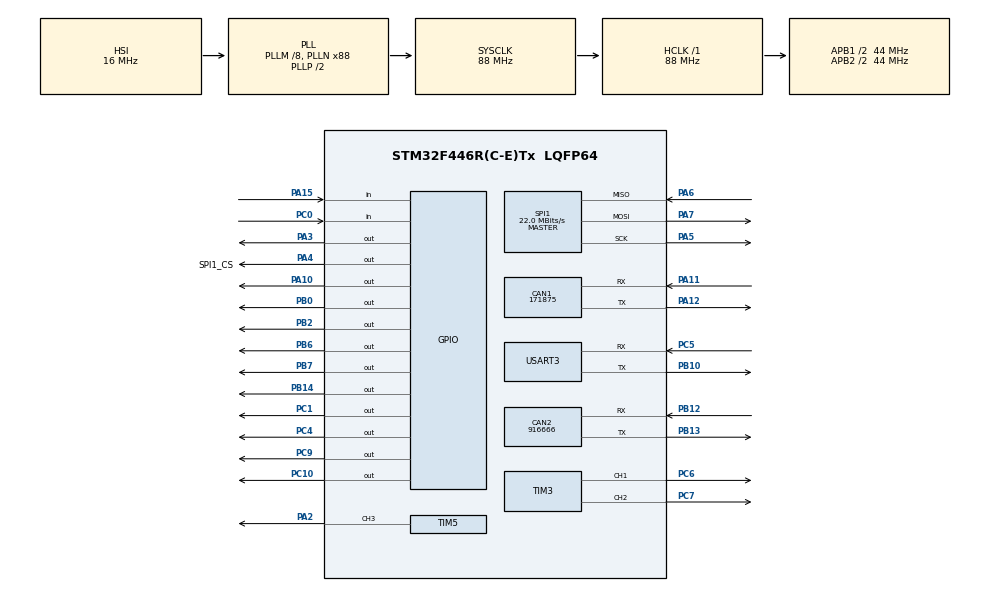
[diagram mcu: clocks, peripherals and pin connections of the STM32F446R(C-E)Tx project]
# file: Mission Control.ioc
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CAN1.AWUM=ENABLE
CAN1.BS1=CAN_BS1_13TQ
CAN1.BS2=CAN_BS2_2TQ
CAN1.CalculateBaudRate=171875
CAN1.CalculateTimeBit=5818
CAN1.CalculateTimeQuantum=363.6363636363636
CAN1.Mode=CAN_MODE_NORMAL
CAN1.NART=ENABLE
CAN2.CalculateBaudRate=916666
CAN2.CalculateTimeBit=1090
CAN2.CalculateTimeQuantum=363.6363636363636
Mcu.Family=STM32F4
Mcu.Name=STM32F446R(C-E)Tx
Mcu.Package=LQFP64
NVIC.PriorityGroup=NVIC_PRIORITYGROUP_4
PA10.Signal=GPIO_Output
PA11.Mode=CAN_Activate
PA11.Signal=CAN1_RX
PA12.Mode=CAN_Activate
PA12.Signal=CAN1_TX
PA13.Mode=Trace_Asynchronous_SW
PA13.Signal=SYS_JTMS-SWDIO
PA14.Mode=Trace_Asynchronous_SW
PA14.Signal=SYS_JTCK-SWCLK
PA15.Signal=GPIO_Input
PA2.Signal=S_TIM5_CH3
PA3.Signal=GPIO_Output
PA4.GPIO_Label=SPI1_CS
PA4.Signal=GPIO_Output
PA5.Mode=Full_Duplex_Master
PA5.Signal=SPI1_SCK
PA6.Mode=Full_Duplex_Master
PA6.Signal=SPI1_MISO
PA7.Mode=Full_Duplex_Master
PA7.Signal=SPI1_MOSI
PB0.Signal=GPIO_Output
PB10.Mode=Asynchronous
PB10.Signal=USART3_TX
PB12.Mode=CAN_Activate
PB12.Signal=CAN2_RX
PB13.Mode=CAN_Activate
PB13.Signal=CAN2_TX
PB14.Signal=GPIO_Output
PB2.Signal=GPIO_Output
PB3.Mode=Trace_Asynchronous_SW
PB3.Signal=SYS_JTDO-SWO
PB6.Signal=GPIO_Output
PB7.Signal=GPIO_Output
PB8.Signal=S_TIM2_CH1_ETR
PC0.Signal=GPIO_Input
PC1.Signal=GPIO_Output
PC10.Signal=GPIO_Output
PC14-OSC32_IN.Signal=RCC_OSC32_IN
PC15-OSC32_OUT.Signal=RCC_OSC32_OUT
PC4.Signal=GPIO_Output
PC5.Mode=Asynchronous
PC5.Signal=USART3_RX
PC6.Signal=S_TIM3_CH1
PC7.Signal=S_TIM3_CH2
PC9.Signal=GPIO_Output
PH0-OSC_IN.Mode=HSE-External-Oscillator
PH0-OSC_IN.Signal=RCC_OSC_IN
PH1-OSC_OUT.Mode=HSE-External-Oscillator
PH1-OSC_OUT.Signal=RCC_OSC_OUT
ProjectManager.HeapSize=0x200
ProjectManager.StackSize=0x400
ProjectManager.TargetToolchain=STM32CubeIDE
RCC.AHBFreq_Value=88000000
RCC.APB1CLKDivider=RCC_HCLK_DIV2
RCC.APB1Freq_Value=44000000
RCC.APB1TimFreq_Value=88000000
RCC.APB2CLKDivider=RCC_HCLK_DIV2
RCC.APB2Freq_Value=44000000
RCC.APB2TimFreq_Value=88000000
RCC.CortexFreq_Value=88000000
RCC.HCLKFreq_Value=88000000
RCC.HSE_VALUE=8000000
RCC.PLLM=8
RCC.PLLN=88
RCC.SYSCLKFreq_VALUE=88000000
RCC.SYSCLKSource=RCC_SYSCLKSOURCE_PLLCLK
RCC.USBFreq_Value=88000000
RCC.VCOOutputFreq_Value=176000000
SH.S_TIM2_CH1_ETR.0=TIM2_CH1
SH.S_TIM3_CH1.0=TIM3_CH1,PWM Generation1 CH1
SH.S_TIM3_CH2.0=TIM3_CH2,PWM Generation2 CH2
SH.S_TIM5_CH3.0=TIM5_CH3,PWM Generation3 CH3
SPI1.CalculateBaudRate=22.0 MBits/s
SPI1.Direction=SPI_DIRECTION_2LINES
SPI1.Mode=SPI_MODE_MASTER
SPI1.VirtualType=VM_MASTER
TIM3.Channel-PWM\ Generation1\ CH1=TIM_CHANNEL_1
TIM3.Channel-PWM\ Generation2\ CH2=TIM_CHANNEL_2
TIM5.Channel-PWM\ Generation3\ CH3=TIM_CHANNEL_3
TIM5.Period=19999
TIM5.Prescaler=87
USART3.VirtualMode=VM_ASYNC
VP_RTC_VS_RTC_Activate.Mode=RTC_Enabled
VP_TIM1_VS_ClockSourceINT.Mode=Internal
board=custom

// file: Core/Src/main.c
/* USER CODE BEGIN Header */
/**
  ******************************************************************************
  * @file           : main.c
  * @brief          : Main program body
  ******************************************************************************
  * @attention
  *
  * Copyright (c) 2025 STMicroelectronics.
  * All rights reserved.
  *
  * This software is licensed under terms that can be found in the LICENSE file
  * in the root directory of this software component.
  * If no LICENSE file comes with this software, it is provided AS-IS.
  *
  ******************************************************************************
  */
/* USER CODE END Header */
#include "main.h"

CAN_HandleTypeDef hcan1;
CAN_HandleTypeDef hcan2;

RTC_HandleTypeDef hrtc;

SPI_HandleTypeDef hspi1;

TIM_HandleTypeDef htim1;
TIM_HandleTypeDef htim3;
TIM_HandleTypeDef htim5;

UART_HandleTypeDef huart3;

void SystemClock_Config(void);
static void MX_GPIO_Init(void);
static void MX_RTC_Init(void);
static void MX_TIM1_Init(void);
static void MX_CAN1_Init(void);
static void MX_CAN2_Init(void);
static void MX_SPI1_Init(void);
static void MX_TIM5_Init(void);
static void MX_USART3_UART_Init(void);
static void MX_TIM3_Init(void);

int main(void)
{

  /* MCU Configuration--------------------------------------------------------*/

  /* Reset of all peripherals, Initializes the Flash interface and the Systick. */
  HAL_Init();

  /* Configure the system clock */
  SystemClock_Config();

  /* Initialize all configured peripherals */
  MX_GPIO_Init();
  MX_RTC_Init();
  MX_TIM1_Init();
  MX_CAN1_Init();
  MX_CAN2_Init();
  MX_SPI1_Init();
  MX_TIM5_Init();
  MX_USART3_UART_Init();
  MX_TIM3_Init();
  /* USER CODE BEGIN 2 */
  for (int i = 0; i < 500; i++) { // Beep for ~1 second (2000 cycles at 2 kHz)
  	          HAL_GPIO_TogglePin(GPIOC, GPIO_PIN_4);
  	          HAL_Delay(.25); // 250 µs delay for 2 kHz (500 µs period)
  	      }
  	      HAL_GPIO_WritePin(GPIOC, GPIO_PIN_4, GPIO_PIN_RESET); // Turn off buzzer

  /* USER CODE END 2 */

  /* Infinite loop */
  while (1)
  {

  }
}

void SystemClock_Config(void)
{
  RCC_OscInitTypeDef RCC_OscInitStruct = {0};
  RCC_ClkInitTypeDef RCC_ClkInitStruct = {0};

  /** Configure the main internal regulator output voltage
  */
  __HAL_RCC_PWR_CLK_ENABLE();
  __HAL_PWR_VOLTAGESCALING_CONFIG(PWR_REGULATOR_VOLTAGE_SCALE3);

  /** Initializes the RCC Oscillators according to the specified parameters
  * in the RCC_OscInitTypeDef structure.
  */
  RCC_OscInitStruct.OscillatorType = RCC_OSCILLATORTYPE_HSI|RCC_OSCILLATORTYPE_LSI;
  RCC_OscInitStruct.LSEState = RCC_LSE_OFF;
  RCC_OscInitStruct.HSIState = RCC_HSI_ON;
  RCC_OscInitStruct.HSICalibrationValue = RCC_HSICALIBRATION_DEFAULT;
  RCC_OscInitStruct.LSIState = RCC_LSI_ON;
  RCC_OscInitStruct.PLL.PLLState = RCC_PLL_ON;
  RCC_OscInitStruct.PLL.PLLSource = RCC_PLLSOURCE_HSI;
  RCC_OscInitStruct.PLL.PLLM = 8;
  RCC_OscInitStruct.PLL.PLLN = 88;
  RCC_OscInitStruct.PLL.PLLP = RCC_PLLP_DIV2;
  RCC_OscInitStruct.PLL.PLLQ = 2;
  RCC_OscInitStruct.PLL.PLLR = 2;
  if (HAL_RCC_OscConfig(&RCC_OscInitStruct) != HAL_OK)
  {
    Error_Handler();
  }

  /** Initializes the CPU, AHB and APB buses clocks
  */
  RCC_ClkInitStruct.ClockType = RCC_CLOCKTYPE_HCLK|RCC_CLOCKTYPE_SYSCLK
                              |RCC_CLOCKTYPE_PCLK1|RCC_CLOCKTYPE_PCLK2;
  RCC_ClkInitStruct.SYSCLKSource = RCC_SYSCLKSOURCE_PLLCLK;
  RCC_ClkInitStruct.AHBCLKDivider = RCC_SYSCLK_DIV1;
  RCC_ClkInitStruct.APB1CLKDivider = RCC_HCLK_DIV2;
  RCC_ClkInitStruct.APB2CLKDivider = RCC_HCLK_DIV2;

  if (HAL_RCC_ClockConfig(&RCC_ClkInitStruct, FLASH_LATENCY_2) != HAL_OK)
  {
    Error_Handler();
  }
}

static void MX_CAN1_Init(void)
{

  hcan1.Instance = CAN1;
  hcan1.Init.Prescaler = 16;
  hcan1.Init.Mode = CAN_MODE_NORMAL;
  hcan1.Init.SyncJumpWidth = CAN_SJW_1TQ;
  hcan1.Init.TimeSeg1 = CAN_BS1_13TQ;
  hcan1.Init.TimeSeg2 = CAN_BS2_2TQ;
  hcan1.Init.TimeTriggeredMode = DISABLE;
  hcan1.Init.AutoBusOff = DISABLE;
  hcan1.Init.AutoWakeUp = ENABLE;
  hcan1.Init.AutoRetransmission = ENABLE;
  hcan1.Init.ReceiveFifoLocked = DISABLE;
  hcan1.Init.TransmitFifoPriority = DISABLE;
  if (HAL_CAN_Init(&hcan1) != HAL_OK)
  {
    Error_Handler();
  }

}

static void MX_CAN2_Init(void)
{

  hcan2.Instance = CAN2;
  hcan2.Init.Prescaler = 16;
  hcan2.Init.Mode = CAN_MODE_NORMAL;
  hcan2.Init.SyncJumpWidth = CAN_SJW_1TQ;
  hcan2.Init.TimeSeg1 = CAN_BS1_1TQ;
  hcan2.Init.TimeSeg2 = CAN_BS2_1TQ;
  hcan2.Init.TimeTriggeredMode = DISABLE;
  hcan2.Init.AutoBusOff = DISABLE;
  hcan2.Init.AutoWakeUp = DISABLE;
  hcan2.Init.AutoRetransmission = DISABLE;
  hcan2.Init.ReceiveFifoLocked = DISABLE;
  hcan2.Init.TransmitFifoPriority = DISABLE;
  if (HAL_CAN_Init(&hcan2) != HAL_OK)
  {
    Error_Handler();
  }

}

static void MX_RTC_Init(void)
{

  /** Initialize RTC Only
  */
  hrtc.Instance = RTC;
  hrtc.Init.HourFormat = RTC_HOURFORMAT_24;
  hrtc.Init.AsynchPrediv = 127;
  hrtc.Init.SynchPrediv = 255;
  hrtc.Init.OutPut = RTC_OUTPUT_DISABLE;
  hrtc.Init.OutPutPolarity = RTC_OUTPUT_POLARITY_HIGH;
  hrtc.Init.OutPutType = RTC_OUTPUT_TYPE_OPENDRAIN;
  if (HAL_RTC_Init(&hrtc) != HAL_OK)
  {
    Error_Handler();
  }

}

static void MX_SPI1_Init(void)
{

  /* SPI1 parameter configuration*/
  hspi1.Instance = SPI1;
  hspi1.Init.Mode = SPI_MODE_MASTER;
  hspi1.Init.Direction = SPI_DIRECTION_2LINES;
  hspi1.Init.DataSize = SPI_DATASIZE_8BIT;
  hspi1.Init.CLKPolarity = SPI_POLARITY_LOW;
  hspi1.Init.CLKPhase = SPI_PHASE_1EDGE;
  hspi1.Init.NSS = SPI_NSS_SOFT;
  hspi1.Init.BaudRatePrescaler = SPI_BAUDRATEPRESCALER_2;
  hspi1.Init.FirstBit = SPI_FIRSTBIT_MSB;
  hspi1.Init.TIMode = SPI_TIMODE_DISABLE;
  hspi1.Init.CRCCalculation = SPI_CRCCALCULATION_DISABLE;
  hspi1.Init.CRCPolynomial = 10;
  if (HAL_SPI_Init(&hspi1) != HAL_OK)
  {
    Error_Handler();
  }

}

static void MX_TIM1_Init(void)
{

  TIM_ClockConfigTypeDef sClockSourceConfig = {0};
  TIM_MasterConfigTypeDef sMasterConfig = {0};

  htim1.Instance = TIM1;
  htim1.Init.Prescaler = 0;
  htim1.Init.CounterMode = TIM_COUNTERMODE_UP;
  htim1.Init.Period = 65535;
  htim1.Init.ClockDivision = TIM_CLOCKDIVISION_DIV1;
  htim1.Init.RepetitionCounter = 0;
  htim1.Init.AutoReloadPreload = TIM_AUTORELOAD_PRELOAD_DISABLE;
  if (HAL_TIM_Base_Init(&htim1) != HAL_OK)
  {
    Error_Handler();
  }
  sClockSourceConfig.ClockSource = TIM_CLOCKSOURCE_INTERNAL;
  if (HAL_TIM_ConfigClockSource(&htim1, &sClockSourceConfig) != HAL_OK)
  {
    Error_Handler();
  }
  sMasterConfig.MasterOutputTrigger = TIM_TRGO_RESET;
  sMasterConfig.MasterSlaveMode = TIM_MASTERSLAVEMODE_DISABLE;
  if (HAL_TIMEx_MasterConfigSynchronization(&htim1, &sMasterConfig) != HAL_OK)
  {
    Error_Handler();
  }

}

static void MX_TIM3_Init(void)
{

  TIM_MasterConfigTypeDef sMasterConfig = {0};
  TIM_OC_InitTypeDef sConfigOC = {0};

  htim3.Instance = TIM3;
  htim3.Init.Prescaler = 0;
  htim3.Init.CounterMode = TIM_COUNTERMODE_UP;
  htim3.Init.Period = 65535;
  htim3.Init.ClockDivision = TIM_CLOCKDIVISION_DIV1;
  htim3.Init.AutoReloadPreload = TIM_AUTORELOAD_PRELOAD_DISABLE;
  if (HAL_TIM_PWM_Init(&htim3) != HAL_OK)
  {
    Error_Handler();
  }
  sMasterConfig.MasterOutputTrigger = TIM_TRGO_RESET;
  sMasterConfig.MasterSlaveMode = TIM_MASTERSLAVEMODE_DISABLE;
  if (HAL_TIMEx_MasterConfigSynchronization(&htim3, &sMasterConfig) != HAL_OK)
  {
    Error_Handler();
  }
  sConfigOC.OCMode = TIM_OCMODE_PWM1;
  sConfigOC.Pulse = 0;
  sConfigOC.OCPolarity = TIM_OCPOLARITY_HIGH;
  sConfigOC.OCFastMode = TIM_OCFAST_DISABLE;
  if (HAL_TIM_PWM_ConfigChannel(&htim3, &sConfigOC, TIM_CHANNEL_1) != HAL_OK)
  {
    Error_Handler();
  }
  if (HAL_TIM_PWM_ConfigChannel(&htim3, &sConfigOC, TIM_CHANNEL_2) != HAL_OK)
  {
    Error_Handler();
  }
  HAL_TIM_MspPostInit(&htim3);

}

static void MX_TIM5_Init(void)
{

  TIM_MasterConfigTypeDef sMasterConfig = {0};
  TIM_OC_InitTypeDef sConfigOC = {0};

  htim5.Instance = TIM5;
  htim5.Init.Prescaler = 87;
  htim5.Init.CounterMode = TIM_COUNTERMODE_UP;
  htim5.Init.Period = 19999;
  htim5.Init.ClockDivision = TIM_CLOCKDIVISION_DIV1;
  htim5.Init.AutoReloadPreload = TIM_AUTORELOAD_PRELOAD_DISABLE;
  if (HAL_TIM_PWM_Init(&htim5) != HAL_OK)
  {
    Error_Handler();
  }
  sMasterConfig.MasterOutputTrigger = TIM_TRGO_RESET;
  sMasterConfig.MasterSlaveMode = TIM_MASTERSLAVEMODE_DISABLE;
  if (HAL_TIMEx_MasterConfigSynchronization(&htim5, &sMasterConfig) != HAL_OK)
  {
    Error_Handler();
  }
  sConfigOC.OCMode = TIM_OCMODE_PWM1;
  sConfigOC.Pulse = 0;
  sConfigOC.OCPolarity = TIM_OCPOLARITY_HIGH;
  sConfigOC.OCFastMode = TIM_OCFAST_DISABLE;
  if (HAL_TIM_PWM_ConfigChannel(&htim5, &sConfigOC, TIM_CHANNEL_3) != HAL_OK)
  {
    Error_Handler();
  }
  HAL_TIM_MspPostInit(&htim5);

}

static void MX_USART3_UART_Init(void)
{

  huart3.Instance = USART3;
  huart3.Init.BaudRate = 115200;
  huart3.Init.WordLength = UART_WORDLENGTH_8B;
  huart3.Init.StopBits = UART_STOPBITS_1;
  huart3.Init.Parity = UART_PARITY_NONE;
  huart3.Init.Mode = UART_MODE_TX_RX;
  huart3.Init.HwFlowCtl = UART_HWCONTROL_NONE;
  huart3.Init.OverSampling = UART_OVERSAMPLING_16;
  if (HAL_UART_Init(&huart3) != HAL_OK)
  {
    Error_Handler();
  }

}

static void MX_GPIO_Init(void)
{
  GPIO_InitTypeDef GPIO_InitStruct = {0};

  /* GPIO Ports Clock Enable */
  __HAL_RCC_GPIOC_CLK_ENABLE();
  __HAL_RCC_GPIOH_CLK_ENABLE();
  __HAL_RCC_GPIOA_CLK_ENABLE();
  __HAL_RCC_GPIOB_CLK_ENABLE();

  /*Configure GPIO pin Output Level */
  HAL_GPIO_WritePin(GPIOC, GPIO_PIN_1|GPIO_PIN_4|GPIO_PIN_9|GPIO_PIN_10, GPIO_PIN_RESET);

  /*Configure GPIO pin Output Level */
  HAL_GPIO_WritePin(GPIOA, GPIO_PIN_3|SPI1_CS_Pin|GPIO_PIN_10, GPIO_PIN_RESET);

  /*Configure GPIO pin Output Level */
  HAL_GPIO_WritePin(GPIOB, GPIO_PIN_0|GPIO_PIN_2|GPIO_PIN_14|GPIO_PIN_6
                          |GPIO_PIN_7, GPIO_PIN_RESET);

  /*Configure GPIO pin : PC0 */
  GPIO_InitStruct.Pin = GPIO_PIN_0;
  GPIO_InitStruct.Mode = GPIO_MODE_INPUT;
  GPIO_InitStruct.Pull = GPIO_NOPULL;
  HAL_GPIO_Init(GPIOC, &GPIO_InitStruct);

  /*Configure GPIO pins : PC1 PC4 PC9 PC10 */
  GPIO_InitStruct.Pin = GPIO_PIN_1|GPIO_PIN_4|GPIO_PIN_9|GPIO_PIN_10;
  GPIO_InitStruct.Mode = GPIO_MODE_OUTPUT_PP;
  GPIO_InitStruct.Pull = GPIO_NOPULL;
  GPIO_InitStruct.Speed = GPIO_SPEED_FREQ_LOW;
  HAL_GPIO_Init(GPIOC, &GPIO_InitStruct);

  /*Configure GPIO pins : PA3 SPI1_CS_Pin PA10 */
  GPIO_InitStruct.Pin = GPIO_PIN_3|SPI1_CS_Pin|GPIO_PIN_10;
  GPIO_InitStruct.Mode = GPIO_MODE_OUTPUT_PP;
  GPIO_InitStruct.Pull = GPIO_NOPULL;
  GPIO_InitStruct.Speed = GPIO_SPEED_FREQ_LOW;
  HAL_GPIO_Init(GPIOA, &GPIO_InitStruct);

  /*Configure GPIO pins : PB0 PB2 PB14 PB6
                           PB7 */
  GPIO_InitStruct.Pin = GPIO_PIN_0|GPIO_PIN_2|GPIO_PIN_14|GPIO_PIN_6
                          |GPIO_PIN_7;
  GPIO_InitStruct.Mode = GPIO_MODE_OUTPUT_PP;
  GPIO_InitStruct.Pull = GPIO_NOPULL;
  GPIO_InitStruct.Speed = GPIO_SPEED_FREQ_LOW;
  HAL_GPIO_Init(GPIOB, &GPIO_InitStruct);

  /*Configure GPIO pin : PA15 */
  GPIO_InitStruct.Pin = GPIO_PIN_15;
  GPIO_InitStruct.Mode = GPIO_MODE_INPUT;
  GPIO_InitStruct.Pull = GPIO_NOPULL;
  HAL_GPIO_Init(GPIOA, &GPIO_InitStruct);

  /*Configure GPIO pin : PB8 */
  GPIO_InitStruct.Pin = GPIO_PIN_8;
  GPIO_InitStruct.Mode = GPIO_MODE_AF_PP;
  GPIO_InitStruct.Pull = GPIO_NOPULL;
  GPIO_InitStruct.Speed = GPIO_SPEED_FREQ_LOW;
  GPIO_InitStruct.Alternate = GPIO_AF1_TIM2;
  HAL_GPIO_Init(GPIOB, &GPIO_InitStruct);

}

void Error_Handler(void)
{
  __disable_irq();
  while (1)
  {
  }
}
